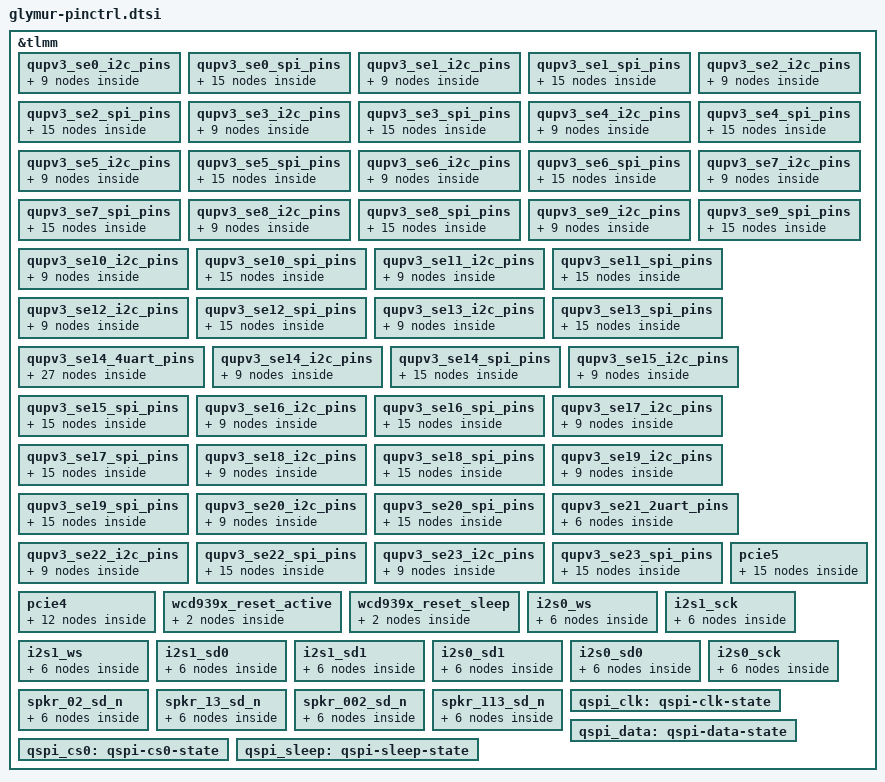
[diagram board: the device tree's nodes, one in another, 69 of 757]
// SPDX-License-Identifier: BSD-3-Clause
/*
 * Copyright (c) Qualcomm Technologies, Inc. and/or its subsidiaries.
 */

&tlmm {
	qupv3_se0_i2c_pins: qupv3_se0_i2c_pins {
		qupv3_se0_i2c_sda_active: qupv3_se0_i2c_sda_active {
			mux {
				pins = "gpio0";
				function = "qup0_se0";
			};

			config {
				pins = "gpio0";
				drive-strength = <2>;
				bias-pull-up;
				qcom,i2c_pull;
			};
		};

		qupv3_se0_i2c_scl_active: qupv3_se0_i2c_scl_active {
			mux {
				pins = "gpio1";
				function = "qup0_se0";
			};

			config {
				pins = "gpio1";
				drive-strength = <2>;
				bias-pull-up;
				qcom,i2c_pull;
			};
		};

		qupv3_se0_i2c_sleep: qupv3_se0_i2c_sleep {
			mux {
				pins = "gpio0", "gpio1";
				function = "gpio";
			};

			config {
				pins = "gpio0", "gpio1";
				drive-strength = <2>;
			};
		};
	};

	qupv3_se0_spi_pins: qupv3_se0_spi_pins {
		qupv3_se0_spi_miso_active: qupv3_se0_spi_miso_active {
			mux {
				pins = "gpio0";
				function = "qup0_se0";
			};

			config {
				pins = "gpio0";
				drive-strength = <6>;
				bias-disable;
			};
		};

		qupv3_se0_spi_mosi_active: qupv3_se0_spi_mosi_active {
			mux {
				pins = "gpio1";
				function = "qup0_se0";
			};

			config {
				pins = "gpio1";
				drive-strength = <6>;
				bias-disable;
			};
		};

		qupv3_se0_spi_clk_active: qupv3_se0_spi_clk_active {
			mux {
				pins = "gpio2";
				function = "qup0_se0";
			};

			config {
				pins = "gpio2";
				drive-strength = <6>;
				bias-disable;
			};
		};

		qupv3_se0_spi_cs_active: qupv3_se0_spi_cs_active {
			mux {
				pins = "gpio3";
				function = "qup0_se0";
			};

			config {
				pins = "gpio3";
				drive-strength = <6>;
				bias-disable;
			};
		};

		qupv3_se0_spi_sleep: qupv3_se0_spi_sleep {
			mux {
				pins = "gpio0", "gpio1",
				       "gpio2", "gpio3";
				function = "gpio";
			};

			config {
				pins = "gpio0", "gpio1",
				       "gpio2", "gpio3";
				drive-strength = <2>;
				bias-disable;
			};
		};
	};

	qupv3_se1_i2c_pins: qupv3_se1_i2c_pins {
		qupv3_se1_i2c_sda_active: qupv3_se1_i2c_sda_active {
			mux {
				pins = "gpio4";
				function = "qup0_se1";
			};

			config {
				pins = "gpio4";
				drive-strength = <2>;
				bias-pull-up;
				qcom,i2c_pull;
			};
		};

		qupv3_se1_i2c_scl_active: qupv3_se1_i2c_scl_active {
			mux {
				pins = "gpio5";
				function = "qup0_se1";
			};

			config {
				pins = "gpio5";
				drive-strength = <2>;
				bias-pull-up;
				qcom,i2c_pull;
			};
		};

		qupv3_se1_i2c_sleep: qupv3_se1_i2c_sleep {
			mux {
				pins = "gpio4", "gpio5";
				function = "gpio";
			};

			config {
				pins = "gpio4", "gpio5";
				drive-strength = <2>;
			};
		};
	};

	qupv3_se1_spi_pins: qupv3_se1_spi_pins {
		qupv3_se1_spi_miso_active: qupv3_se1_spi_miso_active {
			mux {
				pins = "gpio4";
				function = "qup0_se1";
			};

			config {
				pins = "gpio4";
				drive-strength = <6>;
				bias-disable;
			};
		};

		qupv3_se1_spi_mosi_active: qupv3_se1_spi_mosi_active {
			mux {
				pins = "gpio5";
				function = "qup0_se1";
			};

			config {
				pins = "gpio5";
				drive-strength = <6>;
				bias-disable;
			};
		};

		qupv3_se1_spi_clk_active: qupv3_se1_spi_clk_active {
			mux {
				pins = "gpio6";
				function = "qup0_se1";
			};

			config {
				pins = "gpio6";
				drive-strength = <6>;
				bias-disable;
			};
		};

		qupv3_se1_spi_cs_active: qupv3_se1_spi_cs_active {
			mux {
				pins = "gpio7";
				function = "qup0_se1";
			};

			config {
				pins = "gpio7";
				drive-strength = <6>;
				bias-disable;
			};
		};

		qupv3_se1_spi_sleep: qupv3_se1_spi_sleep {
			mux {
				pins = "gpio4", "gpio5",
				       "gpio6", "gpio7";
				function = "gpio";
			};

			config {
				pins = "gpio4", "gpio5",
				       "gpio6", "gpio7";
				drive-strength = <2>;
				bias-disable;
			};
		};
	};

	qupv3_se2_i2c_pins: qupv3_se2_i2c_pins {
		qupv3_se2_i2c_sda_active: qupv3_se2_i2c_sda_active {
			mux {
				pins = "gpio8";
				function = "qup0_se2";
			};

			config {
				pins = "gpio8";
				drive-strength = <2>;
				bias-pull-up;
				qcom,i2c_pull;
			};
		};

		qupv3_se2_i2c_scl_active: qupv3_se2_i2c_scl_active {
			mux {
				pins = "gpio9";
				function = "qup0_se2";
			};

			config {
				pins = "gpio9";
				drive-strength = <2>;
				bias-pull-up;
				qcom,i2c_pull;
			};
		};

		qupv3_se2_i2c_sleep: qupv3_se2_i2c_sleep {
			mux {
				pins = "gpio8", "gpio9";
				function = "gpio";
			};

			config {
				pins = "gpio8", "gpio9";
				drive-strength = <2>;
			};
		};
	};

	qupv3_se2_spi_pins: qupv3_se2_spi_pins {
		qupv3_se2_spi_miso_active: qupv3_se2_spi_miso_active {
			mux {
				pins = "gpio8";
				function = "qup0_se2";
			};

			config {
				pins = "gpio8";
				drive-strength = <6>;
				bias-disable;
			};
		};

		qupv3_se2_spi_mosi_active: qupv3_se2_spi_mosi_active {
			mux {
				pins = "gpio9";
				function = "qup0_se2";
			};

			config {
				pins = "gpio9";
				drive-strength = <6>;
				bias-disable;
			};
		};

		qupv3_se2_spi_clk_active: qupv3_se2_spi_clk_active {
			mux {
				pins = "gpio10";
				function = "qup0_se2";
			};

			config {
				pins = "gpio10";
				drive-strength = <6>;
				bias-disable;
			};
		};

		qupv3_se2_spi_cs_active: qupv3_se2_spi_cs_active {
			mux {
				pins = "gpio11";
				function = "qup0_se2";
			};

			config {
				pins = "gpio11";
				drive-strength = <6>;
				bias-disable;
			};
		};

		qupv3_se2_spi_sleep: qupv3_se2_spi_sleep {
			mux {
				pins = "gpio8", "gpio9",
				       "gpio10", "gpio11";
				function = "gpio";
			};

			config {
				pins = "gpio8", "gpio9",
				       "gpio10", "gpio11";
				drive-strength = <2>;
				bias-disable;
			};
		};
	};

	qupv3_se3_i2c_pins: qupv3_se3_i2c_pins {
		qupv3_se3_i2c_sda_active: qupv3_se3_i2c_sda_active {
			mux {
				pins = "gpio12";
				function = "qup0_se3";
			};

			config {
				pins = "gpio12";
				drive-strength = <2>;
				bias-pull-up;
				qcom,i2c_pull;
			};
		};

		qupv3_se3_i2c_scl_active: qupv3_se3_i2c_scl_active {
			mux {
				pins = "gpio13";
				function = "qup0_se3";
			};

			config {
				pins = "gpio13";
				drive-strength = <2>;
				bias-pull-up;
				qcom,i2c_pull;
			};
		};

		qupv3_se3_i2c_sleep: qupv3_se3_i2c_sleep {
			mux {
				pins = "gpio12", "gpio13";
				function = "gpio";
			};

			config {
				pins = "gpio12", "gpio13";
				drive-strength = <2>;
			};
		};
	};

	qupv3_se3_spi_pins: qupv3_se3_spi_pins {
		qupv3_se3_spi_miso_active: qupv3_se3_spi_miso_active {
			mux {
				pins = "gpio12";
				function = "qup0_se3";
			};

			config {
				pins = "gpio12";
				drive-strength = <6>;
				bias-disable;
			};
		};

		qupv3_se3_spi_mosi_active: qupv3_se3_spi_mosi_active {
			mux {
				pins = "gpio13";
				function = "qup0_se3";
			};

			config {
				pins = "gpio13";
				drive-strength = <6>;
				bias-disable;
			};
		};

		qupv3_se3_spi_clk_active: qupv3_se3_spi_clk_active {
			mux {
				pins = "gpio14";
				function = "qup0_se3";
			};

			config {
				pins = "gpio14";
				drive-strength = <6>;
				bias-disable;
			};
		};

		qupv3_se3_spi_cs_active: qupv3_se3_spi_cs_active {
			mux {
				pins = "gpio15";
				function = "qup0_se3";
			};

			config {
				pins = "gpio15";
				drive-strength = <6>;
				bias-disable;
			};
		};

		qupv3_se3_spi_sleep: qupv3_se3_spi_sleep {
			mux {
				pins = "gpio12", "gpio13",
				       "gpio14", "gpio15";
				function = "gpio";
			};

			config {
				pins = "gpio12", "gpio13",
				       "gpio14", "gpio15";
				drive-strength = <2>;
				bias-disable;
			};
		};
	};

	qupv3_se4_i2c_pins: qupv3_se4_i2c_pins {
		qupv3_se4_i2c_sda_active: qupv3_se4_i2c_sda_active {
			mux {
				pins = "gpio16";
				function = "qup0_se4";
			};

			config {
				pins = "gpio16";
				drive-strength = <2>;
				bias-pull-up;
				qcom,i2c_pull;
			};
		};

		qupv3_se4_i2c_scl_active: qupv3_se4_i2c_scl_active {
			mux {
				pins = "gpio17";
				function = "qup0_se4";
			};

			config {
				pins = "gpio17";
				drive-strength = <2>;
				bias-pull-up;
				qcom,i2c_pull;
			};
		};

		qupv3_se4_i2c_sleep: qupv3_se4_i2c_sleep {
			mux {
				pins = "gpio16", "gpio17";
				function = "gpio";
			};

			config {
				pins = "gpio16", "gpio17";
				drive-strength = <2>;
			};
		};
	};

	qupv3_se4_spi_pins: qupv3_se4_spi_pins {
		qupv3_se4_spi_miso_active: qupv3_se4_spi_miso_active {
			mux {
				pins = "gpio16";
				function = "qup0_se4";
			};

			config {
				pins = "gpio16";
				drive-strength = <6>;
				bias-disable;
			};
		};

		qupv3_se4_spi_mosi_active: qupv3_se4_spi_mosi_active {
			mux {
				pins = "gpio17";
				function = "qup0_se4";
			};

			config {
				pins = "gpio17";
				drive-strength = <6>;
				bias-disable;
			};
		};

		qupv3_se4_spi_clk_active: qupv3_se4_spi_clk_active {
			mux {
				pins = "gpio18";
				function = "qup0_se4";
			};

			config {
				pins = "gpio18";
				drive-strength = <6>;
				bias-disable;
			};
		};

		qupv3_se4_spi_cs_active: qupv3_se4_spi_cs_active {
			mux {
				pins = "gpio19";
				function = "qup0_se4";
			};

			config {
				pins = "gpio19";
				drive-strength = <6>;
				bias-disable;
			};
		};

		qupv3_se4_spi_sleep: qupv3_se4_spi_sleep {
			mux {
				pins = "gpio16", "gpio17",
				       "gpio18", "gpio19";
				function = "gpio";
			};

			config {
				pins = "gpio16", "gpio17",
				       "gpio18", "gpio19";
				drive-strength = <2>;
				bias-disable;
			};
		};
	};

	qupv3_se5_i2c_pins: qupv3_se5_i2c_pins {
		qupv3_se5_i2c_sda_active: qupv3_se5_i2c_sda_active {
			mux {
				pins = "gpio20";
				function = "qup0_se5";
			};

			config {
				pins = "gpio20";
				drive-strength = <2>;
				bias-pull-up;
				qcom,i2c_pull;
			};
		};

		qupv3_se5_i2c_scl_active: qupv3_se5_i2c_scl_active {
			mux {
				pins = "gpio21";
				function = "qup0_se5";
			};

			config {
				pins = "gpio21";
				drive-strength = <2>;
				bias-pull-up;
				qcom,i2c_pull;
			};
		};

		qupv3_se5_i2c_sleep: qupv3_se5_i2c_sleep {
			mux {
				pins = "gpio20", "gpio21";
				function = "gpio";
			};

			config {
				pins = "gpio20", "gpio21";
				drive-strength = <2>;
			};
		};
	};

	qupv3_se5_spi_pins: qupv3_se5_spi_pins {
		qupv3_se5_spi_miso_active: qupv3_se5_spi_miso_active {
			mux {
				pins = "gpio20";
				function = "qup0_se5";
			};

			config {
				pins = "gpio20";
				drive-strength = <6>;
				bias-disable;
			};
		};

		qupv3_se5_spi_mosi_active: qupv3_se5_spi_mosi_active {
			mux {
				pins = "gpio21";
				function = "qup0_se5";
			};

			config {
				pins = "gpio21";
				drive-strength = <6>;
				bias-disable;
			};
		};

		qupv3_se5_spi_clk_active: qupv3_se5_spi_clk_active {
			mux {
				pins = "gpio22";
				function = "qup0_se5";
			};

			config {
				pins = "gpio22";
				drive-strength = <6>;
				bias-disable;
			};
		};

		qupv3_se5_spi_cs_active: qupv3_se5_spi_cs_active {
			mux {
				pins = "gpio23";
				function = "qup0_se5";
			};

			config {
				pins = "gpio23";
				drive-strength = <6>;
				bias-disable;
			};
		};

		qupv3_se5_spi_sleep: qupv3_se5_spi_sleep {
			mux {
				pins = "gpio20", "gpio21",
				       "gpio22", "gpio23";
				function = "gpio";
			};

			config {
				pins = "gpio20", "gpio21",
				       "gpio22", "gpio23";
				drive-strength = <2>;
				bias-disable;
			};
		};
	};

	qupv3_se6_i2c_pins: qupv3_se6_i2c_pins {
		qupv3_se6_i2c_sda_active: qupv3_se6_i2c_sda_active {
			mux {
				pins = "gpio6";
				function = "qup0_se6";
			};

			config {
				pins = "gpio6";
				drive-strength = <2>;
				bias-pull-up;
				qcom,i2c_pull;
			};
		};

		qupv3_se6_i2c_scl_active: qupv3_se6_i2c_scl_active {
			mux {
				pins = "gpio7";
				function = "qup0_se6";
			};

			config {
				pins = "gpio7";
				drive-strength = <2>;
				bias-pull-up;
				qcom,i2c_pull;
			};
		};

		qupv3_se6_i2c_sleep: qupv3_se6_i2c_sleep {
			mux {
				pins = "gpio6", "gpio7";
				function = "gpio";
			};

			config {
				pins = "gpio6", "gpio7";
				drive-strength = <2>;
			};
		};
	};

	qupv3_se6_spi_pins: qupv3_se6_spi_pins {
		qupv3_se6_spi_miso_active: qupv3_se6_spi_miso_active {
			mux {
				pins = "gpio6";
				function = "qup0_se6";
			};

			config {
				pins = "gpio6";
				drive-strength = <6>;
				bias-disable;
			};
		};

		qupv3_se6_spi_mosi_active: qupv3_se6_spi_mosi_active {
			mux {
				pins = "gpio7";
				function = "qup0_se6";
			};

			config {
				pins = "gpio7";
				drive-strength = <6>;
				bias-disable;
			};
		};

		qupv3_se6_spi_clk_active: qupv3_se6_spi_clk_active {
			mux {
				pins = "gpio4";
				function = "qup0_se6";
			};

			config {
				pins = "gpio4";
				drive-strength = <6>;
				bias-disable;
			};
		};

		qupv3_se6_spi_cs_active: qupv3_se6_spi_cs_active {
			mux {
				pins = "gpio5";
				function = "qup0_se6";
			};

			config {
				pins = "gpio5";
				drive-strength = <6>;
				bias-disable;
			};
		};

		qupv3_se6_spi_sleep: qupv3_se6_spi_sleep {
			mux {
				pins = "gpio4", "gpio5",
				       "gpio6", "gpio7";
				function = "gpio";
			};

			config {
				pins = "gpio6", "gpio7",
					"gpio4", "gpio5";
				drive-strength = <2>;
				bias-disable;
			};
		};
	};

	qupv3_se7_i2c_pins: qupv3_se7_i2c_pins {
		qupv3_se7_i2c_sda_active: qupv3_se7_i2c_sda_active {
			mux {
				pins = "gpio14";
				function = "qup0_se7";
			};

			config {
				pins = "gpio14";
				drive-strength = <2>;
				bias-pull-up;
				qcom,i2c_pull;
			};
		};

		qupv3_se7_i2c_scl_active: qupv3_se7_i2c_scl_active {
			mux {
				pins = "gpio15";
				function = "qup0_se7";
			};

			config {
				pins = "gpio15";
				drive-strength = <2>;
				bias-pull-up;
				qcom,i2c_pull;
			};
		};

		qupv3_se7_i2c_sleep: qupv3_se7_i2c_sleep {
			mux {
				pins = "gpio14", "gpio15";
				function = "gpio";
			};

			config {
				pins = "gpio14", "gpio15";
				drive-strength = <2>;
			};
		};
	};

	qupv3_se7_spi_pins: qupv3_se7_spi_pins {
		qupv3_se7_spi_miso_active: qupv3_se7_spi_miso_active {
			mux {
				pins = "gpio14";
				function = "qup0_se7";
			};

			config {
				pins = "gpio14";
				drive-strength = <6>;
				bias-disable;
			};
		};

		qupv3_se7_spi_mosi_active: qupv3_se7_spi_mosi_active {
			mux {
				pins = "gpio15";
				function = "qup0_se7";
			};

			config {
				pins = "gpio15";
				drive-strength = <6>;
				bias-disable;
			};
		};

		qupv3_se7_spi_clk_active: qupv3_se7_spi_clk_active {
			mux {
				pins = "gpio12";
				function = "qup0_se7";
			};

			config {
				pins = "gpio12";
				drive-strength = <6>;
				bias-disable;
			};
		};

		qupv3_se7_spi_cs_active: qupv3_se7_spi_cs_active {
			mux {
				pins = "gpio13";
				function = "qup0_se7";
			};

			config {
				pins = "gpio13";
				drive-strength = <6>;
				bias-disable;
			};
		};

		qupv3_se7_spi_sleep: qupv3_se7_spi_sleep {
			mux {
				pins = "gpio14", "gpio15",
				       "gpio12", "gpio13";
				function = "gpio";
			};

			config {
				pins = "gpio14", "gpio15",
				       "gpio12", "gpio13";
				drive-strength = <2>;
				bias-disable;
			};
		};
	};

	qupv3_se8_i2c_pins: qupv3_se8_i2c_pins {
		qupv3_se8_i2c_sda_active: qupv3_se8_i2c_sda_active {
			mux {
				pins = "gpio32";
				function = "qup1_se0";
			};

			config {
				pins = "gpio32";
				drive-strength = <2>;
				bias-pull-up;
				qcom,i2c_pull;
			};
		};

		qupv3_se8_i2c_scl_active: qupv3_se8_i2c_scl_active {
			mux {
				pins = "gpio33";
				function = "qup1_se0";
			};

			config {
				pins = "gpio33";
				drive-strength = <2>;
				bias-pull-up;
				qcom,i2c_pull;
			};
		};

		qupv3_se8_i2c_sleep: qupv3_se8_i2c_sleep {
			mux {
				pins = "gpio32", "gpio33";
				function = "gpio";
			};

			config {
				pins = "gpio32", "gpio33";
				drive-strength = <2>;
			};
		};
	};

	qupv3_se8_spi_pins: qupv3_se8_spi_pins {
		qupv3_se8_spi_miso_active: qupv3_se8_spi_miso_active {
			mux {
				pins = "gpio32";
				function = "qup1_se0";
			};

			config {
				pins = "gpio32";
				drive-strength = <6>;
				bias-disable;
			};
		};

		qupv3_se8_spi_mosi_active: qupv3_se8_spi_mosi_active {
			mux {
				pins = "gpio33";
				function = "qup1_se0";
			};

			config {
				pins = "gpio33";
				drive-strength = <6>;
				bias-disable;
			};
		};

		qupv3_se8_spi_clk_active: qupv3_se8_spi_clk_active {
			mux {
				pins = "gpio34";
				function = "qup1_se0";
			};

			config {
				pins = "gpio34";
				drive-strength = <6>;
				bias-disable;
			};
		};

		qupv3_se8_spi_cs_active: qupv3_se8_spi_cs_active {
			mux {
				pins = "gpio35";
				function = "qup1_se0";
			};

			config {
				pins = "gpio35";
				drive-strength = <6>;
				bias-disable;
			};
		};

		qupv3_se8_spi_sleep: qupv3_se8_spi_sleep {
			mux {
				pins = "gpio32", "gpio33",
				       "gpio34", "gpio35";
				function = "gpio";
			};

			config {
				pins = "gpio32", "gpio33",
				       "gpio34", "gpio35";
				drive-strength = <2>;
				bias-disable;
			};
		};
	};

	qupv3_se9_i2c_pins: qupv3_se9_i2c_pins {
		qupv3_se9_i2c_sda_active: qupv3_se9_i2c_sda_active {
			mux {
				pins = "gpio36";
				function = "qup1_se1";
			};

			config {
				pins = "gpio36";
				drive-strength = <2>;
				bias-pull-up;
				qcom,i2c_pull;
			};
		};

		qupv3_se9_i2c_scl_active: qupv3_se9_i2c_scl_active {
			mux {
				pins = "gpio37";
				function = "qup1_se1";
			};

			config {
				pins = "gpio37";
				drive-strength = <2>;
				bias-pull-up;
				qcom,i2c_pull;
			};
		};

		qupv3_se9_i2c_sleep: qupv3_se9_i2c_sleep {
			mux {
				pins = "gpio36", "gpio37";
				function = "gpio";
			};

			config {
				pins = "gpio36", "gpio37";
				drive-strength = <2>;
			};
		};
	};

	qupv3_se9_spi_pins: qupv3_se9_spi_pins {
		qupv3_se9_spi_miso_active: qupv3_se9_spi_miso_active {
			mux {
				pins = "gpio36";
				function = "qup1_se1";
			};

			config {
				pins = "gpio36";
				drive-strength = <6>;
				bias-disable;
			};
		};

		qupv3_se9_spi_mosi_active: qupv3_se9_spi_mosi_active {
			mux {
				pins = "gpio37";
				function = "qup1_se1";
			};

			config {
				pins = "gpio37";
				drive-strength = <6>;
				bias-disable;
			};
		};

		qupv3_se9_spi_clk_active: qupv3_se9_spi_clk_active {
			mux {
				pins = "gpio38";
				function = "qup1_se1";
			};

			config {
				pins = "gpio38";
				drive-strength = <6>;
				bias-disable;
			};
		};

		qupv3_se9_spi_cs_active: qupv3_se9_spi_cs_active {
			mux {
				pins = "gpio39";
				function = "qup1_se1";
			};

			config {
				pins = "gpio39";
				drive-strength = <6>;
				bias-disable;
			};
		};

		qupv3_se9_spi_sleep: qupv3_se9_spi_sleep {
			mux {
				pins = "gpio36", "gpio37",
				       "gpio38", "gpio39";
				function = "gpio";
			};

			config {
				pins = "gpio36", "gpio37",
				       "gpio38", "gpio39";
				drive-strength = <2>;
				bias-disable;
			};
		};
	};

	qupv3_se10_i2c_pins: qupv3_se10_i2c_pins {
		qupv3_se10_i2c_sda_active: qupv3_se10_i2c_sda_active {
			mux {
				pins = "gpio40";
				function = "qup1_se2";
			};

			config {
				pins = "gpio40";
				drive-strength = <2>;
				bias-pull-up;
				qcom,i2c_pull;
			};
		};

		qupv3_se10_i2c_scl_active: qupv3_se10_i2c_scl_active {
			mux {
				pins = "gpio41";
				function = "qup1_se2";
			};

			config {
				pins = "gpio41";
				drive-strength = <2>;
				bias-pull-up;
				qcom,i2c_pull;
			};
		};

		qupv3_se10_i2c_sleep: qupv3_se10_i2c_sleep {
			mux {
				pins = "gpio40", "gpio41";
				function = "gpio";
			};

			config {
				pins = "gpio40", "gpio41";
				drive-strength = <2>;
			};
		};
	};

	qupv3_se10_spi_pins: qupv3_se10_spi_pins {
		qupv3_se10_spi_miso_active: qupv3_se10_spi_miso_active {
			mux {
				pins = "gpio40";
				function = "qup1_se2";
			};

			config {
				pins = "gpio40";
				drive-strength = <6>;
				bias-disable;
			};
		};

		qupv3_se10_spi_mosi_active: qupv3_se10_spi_mosi_active {
			mux {
				pins = "gpio41";
				function = "qup1_se2";
			};

			config {
				pins = "gpio41";
				drive-strength = <6>;
				bias-disable;
			};
		};

		qupv3_se10_spi_clk_active: qupv3_se10_spi_clk_active {
			mux {
				pins = "gpio42";
				function = "qup1_se2";
			};

			config {
				pins = "gpio42";
				drive-strength = <6>;
				bias-disable;
			};
		};

		qupv3_se10_spi_cs_active: qupv3_se10_spi_cs_active {
			mux {
				pins = "gpio43";
				function = "qup1_se2";
			};

			config {
				pins = "gpio43";
				drive-strength = <6>;
				bias-disable;
			};
		};

		qupv3_se10_spi_sleep: qupv3_se10_spi_sleep {
			mux {
				pins = "gpio40", "gpio41",
				       "gpio42", "gpio43";
				function = "gpio";
			};

			config {
				pins = "gpio40", "gpio41",
				       "gpio42", "gpio43";
				drive-strength = <2>;
				bias-disable;
			};
		};
	};

	qupv3_se11_i2c_pins: qupv3_se11_i2c_pins {
		qupv3_se11_i2c_sda_active: qupv3_se11_i2c_sda_active {
			mux {
				pins = "gpio44";
				function = "qup1_se3";
			};

			config {
				pins = "gpio44";
				drive-strength = <2>;
				bias-pull-up;
				qcom,i2c_pull;
			};
		};

		qupv3_se11_i2c_scl_active: qupv3_se11_i2c_scl_active {
			mux {
				pins = "gpio45";
				function = "qup1_se3";
			};

			config {
				pins = "gpio45";
				drive-strength = <2>;
				bias-pull-up;
				qcom,i2c_pull;
			};
		};

		qupv3_se11_i2c_sleep: qupv3_se11_i2c_sleep {
			mux {
				pins = "gpio44", "gpio45";
				function = "gpio";
			};

			config {
				pins = "gpio44", "gpio45";
				drive-strength = <2>;
			};
		};
	};

	qupv3_se11_spi_pins: qupv3_se11_spi_pins {
		qupv3_se11_spi_miso_active: qupv3_se11_spi_miso_active {
			mux {
				pins = "gpio44";
				function = "qup1_se3";
			};

			config {
				pins = "gpio44";
				drive-strength = <6>;
				bias-disable;
			};
		};

		qupv3_se11_spi_mosi_active: qupv3_se11_spi_mosi_active {
			mux {
				pins = "gpio45";
				function = "qup1_se3";
			};

			config {
				pins = "gpio45";
				drive-strength = <6>;
				bias-disable;
			};
		};

		qupv3_se11_spi_clk_active: qupv3_se11_spi_clk_active {
			mux {
				pins = "gpio46";
				function = "qup1_se3";
			};

			config {
				pins = "gpio46";
				drive-strength = <6>;
				bias-disable;
			};
		};

		qupv3_se11_spi_cs_active: qupv3_se11_spi_cs_active {
			mux {
				pins = "gpio47";
				function = "qup1_se3";
			};

			config {
				pins = "gpio47";
				drive-strength = <6>;
				bias-disable;
			};
		};

		qupv3_se11_spi_sleep: qupv3_se11_spi_sleep {
			mux {
				pins = "gpio44", "gpio45",
				       "gpio46", "gpio47";
				function = "gpio";
			};

			config {
				pins = "gpio44", "gpio45",
				       "gpio46", "gpio47";
				drive-strength = <2>;
				bias-disable;
			};
		};
	};

	qupv3_se12_i2c_pins: qupv3_se12_i2c_pins {
		qupv3_se12_i2c_sda_active: qupv3_se12_i2c_sda_active {
			mux {
				pins = "gpio48";
				function = "qup1_se4";
			};

			config {
				pins = "gpio48";
				drive-strength = <2>;
				bias-pull-up;
				qcom,i2c_pull;
			};
		};

		qupv3_se12_i2c_scl_active: qupv3_se12_i2c_scl_active {
			mux {
				pins = "gpio49";
				function = "qup1_se4";
			};

			config {
				pins = "gpio49";
				drive-strength = <2>;
				bias-pull-up;
				qcom,i2c_pull;
			};
		};

		qupv3_se12_i2c_sleep: qupv3_se12_i2c_sleep {
			mux {
				pins = "gpio48", "gpio49";
				function = "gpio";
			};

			config {
				pins = "gpio48", "gpio49";
				drive-strength = <2>;
			};
		};
	};

	qupv3_se12_spi_pins: qupv3_se12_spi_pins {
		qupv3_se12_spi_miso_active: qupv3_se12_spi_miso_active {
			mux {
				pins = "gpio48";
				function = "qup1_se4";
			};

			config {
				pins = "gpio48";
				drive-strength = <6>;
				bias-disable;
			};
		};

		qupv3_se12_spi_mosi_active: qupv3_se12_spi_mosi_active {
			mux {
				pins = "gpio49";
				function = "qup1_se4";
			};

			config {
				pins = "gpio49";
				drive-strength = <6>;
				bias-disable;
			};
		};

		qupv3_se12_spi_clk_active: qupv3_se12_spi_clk_active {
			mux {
				pins = "gpio50";
				function = "qup1_se4";
			};

			config {
				pins = "gpio50";
				drive-strength = <6>;
				bias-disable;
			};
		};

		qupv3_se12_spi_cs_active: qupv3_se12_spi_cs_active {
			mux {
				pins = "gpio51";
				function = "qup1_se4";
			};

			config {
				pins = "gpio51";
				drive-strength = <6>;
				bias-disable;
			};
		};

		qupv3_se12_spi_sleep: qupv3_se12_spi_sleep {
			mux {
				pins = "gpio48", "gpio49",
				       "gpio50", "gpio51";
				function = "gpio";
			};

			config {
				pins = "gpio48", "gpio49",
				       "gpio50", "gpio51";
				drive-strength = <2>;
				bias-disable;
			};
		};
	};

	qupv3_se13_i2c_pins: qupv3_se13_i2c_pins {
		qupv3_se13_i2c_sda_active: qupv3_se13_i2c_sda_active {
			mux {
				pins = "gpio52";
				function = "qup1_se5";
			};

			config {
				pins = "gpio52";
				drive-strength = <2>;
				bias-pull-up;
				qcom,i2c_pull;
			};
		};

		qupv3_se13_i2c_scl_active: qupv3_se13_i2c_scl_active {
			mux {
				pins = "gpio53";
				function = "qup1_se5";
			};

			config {
				pins = "gpio53";
				drive-strength = <2>;
				bias-pull-up;
				qcom,i2c_pull;
			};
		};

		qupv3_se13_i2c_sleep: qupv3_se13_i2c_sleep {
			mux {
				pins = "gpio52", "gpio53";
				function = "gpio";
			};

			config {
				pins = "gpio52", "gpio53";
				drive-strength = <2>;
			};
		};
	};

	qupv3_se13_spi_pins: qupv3_se13_spi_pins {
		qupv3_se13_spi_miso_active: qupv3_se13_spi_miso_active {
			mux {
				pins = "gpio52";
				function = "qup1_se5";
			};

			config {
				pins = "gpio52";
				drive-strength = <6>;
				bias-disable;
			};
		};

		qupv3_se13_spi_mosi_active: qupv3_se13_spi_mosi_active {
			mux {
				pins = "gpio53";
				function = "qup1_se5";
			};

			config {
				pins = "gpio53";
				drive-strength = <6>;
				bias-disable;
			};
		};

		qupv3_se13_spi_clk_active: qupv3_se13_spi_clk_active {
			mux {
				pins = "gpio54";
				function = "qup1_se5";
			};

			config {
				pins = "gpio54";
				drive-strength = <6>;
				bias-disable;
			};
		};

		qupv3_se13_spi_cs_active: qupv3_se13_spi_cs_active {
			mux {
				pins = "gpio55";
				function = "qup1_se5";
			};

			config {
				pins = "gpio55";
				drive-strength = <6>;
				bias-disable;
			};
		};

		qupv3_se13_spi_sleep: qupv3_se13_spi_sleep {
			mux {
				pins = "gpio52", "gpio53",
				       "gpio54", "gpio55";
				function = "gpio";
			};

			config {
				pins = "gpio52", "gpio53",
				       "gpio54", "gpio55";
				drive-strength = <2>;
				bias-disable;
			};
		};
	};

	qupv3_se14_4uart_pins: qupv3_se14_4uart_pins {
		qupv3_se14_default_cts: qupv3_se14_default_cts {
			mux {
				pins = "gpio56";
				function = "gpio";
			};

			config {
				pins = "gpio56";
				drive-strength = <2>;
				bias-disable;
			};
		};

		qupv3_se14_default_rts: qupv3_se14_default_rts {
			mux {
				pins = "gpio57";
				function = "gpio";
			};

			config {
				pins = "gpio57";
				drive-strength = <2>;
				bias-pull-down;
			};
		};

		qupv3_se14_default_tx: qupv3_se14_default_tx {
			mux {
				pins = "gpio58";
				function = "gpio";
			};

			config {
				pins = "gpio58";
				drive-strength = <2>;
				bias-pull-up;
			};
		};

		qupv3_se14_default_rx: qupv3_se14_default_rx {
			mux {
				pins = "gpio59";
				function = "gpio";
			};

			config {
				pins = "gpio59";
				drive-strength = <2>;
				bias-pull-down;
			};
		};

		qupv3_se14_cts: qupv3_se14_cts {
			mux {
				pins = "gpio56";
				function = "qup1_se6";
			};

			config {
				pins = "gpio56";
				drive-strength = <2>;
				bias-disable;
			};
	       };

		qupv3_se14_rts: qupv3_se14_rts {
			mux {
				pins = "gpio57";
				function = "qup1_se6";
			};

			config {
				pins = "gpio57";
				drive-strength = <2>;
				bias-pull-down;
			};
	       };

		qupv3_se14_tx: qupv3_se14_tx {
			mux {
				pins = "gpio58";
				function = "qup1_se6";
			};

			config {
				pins = "gpio58";
				drive-strength = <2>;
				bias-pull-up;
			};
		};

		qupv3_se14_rx_active: qupv3_se14_rx_active {
			mux {
				pins = "gpio59";
				function = "qup1_se6";
			};

			config {
				pins = "gpio59";
				drive-strength = <2>;
				bias-disable;
			};
		};

		/* RX to be in gpio mode for sleep config */
		qupv3_se14_rx_wake: qupv3_se14_rx_wake {
			mux {
				pins = "gpio59";
				function = "gpio";
			};

			config {
				pins = "gpio59";
				drive-strength = <2>;
				bias-disable;
			};
		};
	};

	qupv3_se14_i2c_pins: qupv3_se14_i2c_pins {
		qupv3_se14_i2c_sda_active: qupv3_se14_i2c_sda_active {
			mux {
				pins = "gpio56";
				function = "qup1_se6";
			};

			config {
				pins = "gpio56";
				drive-strength = <2>;
				bias-pull-up;
				qcom,i2c_pull;
			};
		};

		qupv3_se14_i2c_scl_active: qupv3_se14_i2c_scl_active {
			mux {
				pins = "gpio57";
				function = "qup1_se6";
			};

			config {
				pins = "gpio57";
				drive-strength = <2>;
				bias-pull-up;
				qcom,i2c_pull;
			};
		};

		qupv3_se14_i2c_sleep: qupv3_se14_i2c_sleep {
			mux {
				pins = "gpio56", "gpio57";
				function = "gpio";
			};

			config {
				pins = "gpio56", "gpio57";
				drive-strength = <2>;
			};
		};
	};

	qupv3_se14_spi_pins: qupv3_se14_spi_pins {
		qupv3_se14_spi_miso_active: qupv3_se14_spi_miso_active {
			mux {
				pins = "gpio56";
				function = "qup1_se6";
			};

			config {
				pins = "gpio56";
				drive-strength = <6>;
				bias-disable;
			};
		};

		qupv3_se14_spi_mosi_active: qupv3_se14_spi_mosi_active {
			mux {
				pins = "gpio57";
				function = "qup1_se6";
			};

			config {
				pins = "gpio57";
				drive-strength = <6>;
				bias-disable;
			};
		};

		qupv3_se14_spi_clk_active: qupv3_se14_spi_clk_active {
			mux {
				pins = "gpio58";
				function = "qup1_se6";
			};

			config {
				pins = "gpio58";
				drive-strength = <6>;
				bias-disable;
			};
		};

		qupv3_se14_spi_cs_active: qupv3_se14_spi_cs_active {
			mux {
				pins = "gpio59";
				function = "qup1_se6";
			};

			config {
				pins = "gpio59";
				drive-strength = <6>;
				bias-disable;
			};
		};

		qupv3_se14_spi_sleep: qupv3_se14_spi_sleep {
			mux {
				pins = "gpio56", "gpio57",
				       "gpio58", "gpio59";
				function = "gpio";
			};

			config {
				pins = "gpio56", "gpio57",
				       "gpio58", "gpio59";
				drive-strength = <2>;
				bias-disable;
			};
		};
	};

	qupv3_se15_i2c_pins: qupv3_se15_i2c_pins {
		qupv3_se15_i2c_sda_active: qupv3_se15_i2c_sda_active {
			mux {
				pins = "gpio54";
				function = "qup1_se7";
			};

			config {
				pins = "gpio54";
				drive-strength = <2>;
				bias-pull-up;
				qcom,i2c_pull;
			};
		};

		qupv3_se15_i2c_scl_active: qupv3_se15_i2c_scl_active {
			mux {
				pins = "gpio55";
				function = "qup1_se7";
			};

			config {
				pins = "gpio55";
				drive-strength = <2>;
				bias-pull-up;
				qcom,i2c_pull;
			};
		};

		qupv3_se15_i2c_sleep: qupv3_se15_i2c_sleep {
			mux {
				pins = "gpio54", "gpio55";
				function = "gpio";
			};

			config {
				pins = "gpio54", "gpio55";
				drive-strength = <2>;
			};
		};
	};

	qupv3_se15_spi_pins: qupv3_se15_spi_pins {
		qupv3_se15_spi_miso_active: qupv3_se15_spi_miso_active {
			mux {
				pins = "gpio54";
				function = "qup1_se7";
			};

			config {
				pins = "gpio54";
				drive-strength = <6>;
				bias-disable;
			};
		};

		qupv3_se15_spi_mosi_active: qupv3_se15_spi_mosi_active {
			mux {
				pins = "gpio55";
				function = "qup1_se7";
			};

			config {
				pins = "gpio55";
				drive-strength = <6>;
				bias-disable;
			};
		};

		qupv3_se15_spi_clk_active: qupv3_se15_spi_clk_active {
			mux {
				pins = "gpio52";
				function = "qup1_se7";
			};

			config {
				pins = "gpio52";
				drive-strength = <6>;
				bias-disable;
			};
		};

		qupv3_se15_spi_cs_active: qupv3_se15_spi_cs_active {
			mux {
				pins = "gpio53";
				function = "qup1_se7";
			};

			config {
				pins = "gpio53";
				drive-strength = <6>;
				bias-disable;
			};
		};

		qupv3_se15_spi_sleep: qupv3_se15_spi_sleep {
			mux {
				pins = "gpio54", "gpio55",
				       "gpio52", "gpio53";
				function = "gpio";
			};

			config {
				pins = "gpio54", "gpio55",
				       "gpio52", "gpio53";
				drive-strength = <2>;
				bias-disable;
			};
		};
	};

	qupv3_se16_i2c_pins: qupv3_se16_i2c_pins {
		qupv3_se16_i2c_sda_active: qupv3_se16_i2c_sda_active {
			mux {
				pins = "gpio64";
				function = "qup2_se0";
			};

			config {
				pins = "gpio64";
				drive-strength = <2>;
				bias-pull-up;
				qcom,i2c_pull;
			};
		};

		qupv3_se16_i2c_scl_active: qupv3_se16_i2c_scl_active {
			mux {
				pins = "gpio65";
				function = "qup2_se0";
			};

			config {
				pins = "gpio65";
				drive-strength = <2>;
				bias-pull-up;
				qcom,i2c_pull;
			};
		};

		qupv3_se16_i2c_sleep: qupv3_se16_i2c_sleep {
			mux {
				pins = "gpio64", "gpio65";
				function = "gpio";
			};

			config {
				pins = "gpio64", "gpio65";
				drive-strength = <2>;
			};
		};
	};

	qupv3_se16_spi_pins: qupv3_se16_spi_pins {
		qupv3_se16_spi_miso_active: qupv3_se16_spi_miso_active {
			mux {
				pins = "gpio64";
				function = "qup2_se0";
			};

			config {
				pins = "gpio64";
				drive-strength = <6>;
				bias-disable;
			};
		};

		qupv3_se16_spi_mosi_active: qupv3_se16_spi_mosi_active {
			mux {
				pins = "gpio65";
				function = "qup2_se0";
			};

			config {
				pins = "gpio65";
				drive-strength = <6>;
				bias-disable;
			};
		};

		qupv3_se16_spi_clk_active: qupv3_se16_spi_clk_active {
			mux {
				pins = "gpio66";
				function = "qup2_se0";
			};

			config {
				pins = "gpio66";
				drive-strength = <6>;
				bias-disable;
			};
		};

		qupv3_se16_spi_cs_active: qupv3_se16_spi_cs_active {
			mux {
				pins = "gpio67";
				function = "qup2_se0";
			};

			config {
				pins = "gpio67";
				drive-strength = <6>;
				bias-disable;
			};
		};

		qupv3_se16_spi_sleep: qupv3_se16_spi_sleep {
			mux {
				pins = "gpio64", "gpio65",
				       "gpio66", "gpio67";
				function = "gpio";
			};

			config {
				pins = "gpio64", "gpio65",
				       "gpio66", "gpio67";
				drive-strength = <2>;
				bias-disable;
			};
		};
	};

	qupv3_se17_i2c_pins: qupv3_se17_i2c_pins {
		qupv3_se17_i2c_sda_active: qupv3_se17_i2c_sda_active {
			mux {
				pins = "gpio68";
				function = "qup2_se1";
			};

			config {
				pins = "gpio68";
				drive-strength = <2>;
				bias-pull-up;
				qcom,i2c_pull;
			};
		};

		qupv3_se17_i2c_scl_active: qupv3_se17_i2c_scl_active {
			mux {
				pins = "gpio69";
				function = "qup2_se1";
			};

			config {
				pins = "gpio69";
				drive-strength = <2>;
				bias-pull-up;
				qcom,i2c_pull;
			};
		};

		qupv3_se17_i2c_sleep: qupv3_se17_i2c_sleep {
			mux {
				pins = "gpio68", "gpio69";
				function = "gpio";
			};

			config {
				pins = "gpio68", "gpio69";
				drive-strength = <2>;
			};
		};
	};

	qupv3_se17_spi_pins: qupv3_se17_spi_pins {
		qupv3_se17_spi_miso_active: qupv3_se17_spi_miso_active {
			mux {
				pins = "gpio68";
				function = "qup2_se1";
			};

			config {
				pins = "gpio68";
				drive-strength = <6>;
				bias-disable;
			};
		};

		qupv3_se17_spi_mosi_active: qupv3_se17_spi_mosi_active {
			mux {
				pins = "gpio69";
				function = "qup2_se1";
			};

			config {
				pins = "gpio69";
				drive-strength = <6>;
				bias-disable;
			};
		};

		qupv3_se17_spi_clk_active: qupv3_se17_spi_clk_active {
			mux {
				pins = "gpio70";
				function = "qup2_se1";
			};

			config {
				pins = "gpio70";
				drive-strength = <6>;
				bias-disable;
			};
		};

		qupv3_se17_spi_cs_active: qupv3_se17_spi_cs_active {
			mux {
				pins = "gpio71";
				function = "qup2_se1";
			};

			config {
				pins = "gpio71";
				drive-strength = <6>;
				bias-disable;
			};
		};

		qupv3_se17_spi_sleep: qupv3_se17_spi_sleep {
			mux {
				pins = "gpio68", "gpio69",
				       "gpio70", "gpio71";
				function = "gpio";
			};

			config {
				pins = "gpio68", "gpio69",
				       "gpio70", "gpio71";
				drive-strength = <2>;
				bias-disable;
			};
		};
	};

	qupv3_se18_i2c_pins: qupv3_se18_i2c_pins {
		qupv3_se18_i2c_sda_active: qupv3_se18_i2c_sda_active {
			mux {
				pins = "gpio72";
				function = "qup2_se2";
			};

			config {
				pins = "gpio72";
				drive-strength = <2>;
				bias-pull-up;
				qcom,i2c_pull;
			};
		};

		qupv3_se18_i2c_scl_active: qupv3_se18_i2c_scl_active {
			mux {
				pins = "gpio73";
				function = "qup2_se2";
			};

			config {
				pins = "gpio73";
				drive-strength = <2>;
				bias-pull-up;
				qcom,i2c_pull;
			};
		};

		qupv3_se18_i2c_sleep: qupv3_se18_i2c_sleep {
			mux {
				pins = "gpio72", "gpio73";
				function = "gpio";
			};

			config {
				pins = "gpio72", "gpio73";
				drive-strength = <2>;
			};
		};
	};

	qupv3_se18_spi_pins: qupv3_se18_spi_pins {
		qupv3_se18_spi_miso_active: qupv3_se18_spi_miso_active {
			mux {
				pins = "gpio72";
				function = "qup2_se2";
			};

			config {
				pins = "gpio72";
				drive-strength = <6>;
				bias-disable;
			};
		};

		qupv3_se18_spi_mosi_active: qupv3_se18_spi_mosi_active {
			mux {
				pins = "gpio73";
				function = "qup2_se2";
			};

			config {
				pins = "gpio73";
				drive-strength = <6>;
				bias-disable;
			};
		};

		qupv3_se18_spi_clk_active: qupv3_se18_spi_clk_active {
			mux {
				pins = "gpio74";
				function = "qup2_se2";
			};

			config {
				pins = "gpio74";
				drive-strength = <6>;
				bias-disable;
			};
		};

		qupv3_se18_spi_cs_active: qupv3_se18_spi_cs_active {
			mux {
				pins = "gpio75";
				function = "qup2_se2";
			};

			config {
				pins = "gpio75";
				drive-strength = <6>;
				bias-disable;
			};
		};

		qupv3_se18_spi_sleep: qupv3_se18_spi_sleep {
			mux {
				pins = "gpio72", "gpio73",
				       "gpio74", "gpio75";
				function = "gpio";
			};

			config {
				pins = "gpio72", "gpio73",
				       "gpio74", "gpio75";
				drive-strength = <2>;
				bias-disable;
			};
		};
	};

	qupv3_se19_i2c_pins: qupv3_se19_i2c_pins {
		qupv3_se19_i2c_sda_active: qupv3_se19_i2c_sda_active {
			mux {
				pins = "gpio76";
				function = "qup2_se3";
			};

			config {
				pins = "gpio76";
				drive-strength = <2>;
				bias-pull-up;
				qcom,i2c_pull;
			};
		};

		qupv3_se19_i2c_scl_active: qupv3_se19_i2c_scl_active {
			mux {
				pins = "gpio77";
				function = "qup2_se3";
			};

			config {
				pins = "gpio77";
				drive-strength = <2>;
				bias-pull-up;
				qcom,i2c_pull;
			};
		};

		qupv3_se19_i2c_sleep: qupv3_se19_i2c_sleep {
			mux {
				pins = "gpio76", "gpio77";
				function = "gpio";
			};

			config {
				pins = "gpio76", "gpio77";
				drive-strength = <2>;
			};
		};
	};

	qupv3_se19_spi_pins: qupv3_se19_spi_pins {
		qupv3_se19_spi_miso_active: qupv3_se19_spi_miso_active {
			mux {
				pins = "gpio76";
				function = "qup2_se3";
			};

			config {
				pins = "gpio76";
				drive-strength = <6>;
				bias-disable;
			};
		};

		qupv3_se19_spi_mosi_active: qupv3_se19_spi_mosi_active {
			mux {
				pins = "gpio77";
				function = "qup2_se3";
			};

			config {
				pins = "gpio77";
				drive-strength = <6>;
				bias-disable;
			};
		};

		qupv3_se19_spi_clk_active: qupv3_se19_spi_clk_active {
			mux {
				pins = "gpio78";
				function = "qup2_se3";
			};

			config {
				pins = "gpio78";
				drive-strength = <6>;
				bias-disable;
			};
		};

		qupv3_se19_spi_cs_active: qupv3_se19_spi_cs_active {
			mux {
				pins = "gpio79";
				function = "qup2_se3";
			};

			config {
				pins = "gpio79";
				drive-strength = <6>;
				bias-disable;
			};
		};

		qupv3_se19_spi_sleep: qupv3_se19_spi_sleep {
			mux {
				pins = "gpio76", "gpio77",
				       "gpio78", "gpio79";
				function = "gpio";
			};

			config {
				pins = "gpio76", "gpio77",
				       "gpio78", "gpio79";
				drive-strength = <2>;
				bias-disable;
			};
		};
	};

	qupv3_se20_i2c_pins: qupv3_se20_i2c_pins {
		qupv3_se20_i2c_sda_active: qupv3_se20_i2c_sda_active {
			mux {
				pins = "gpio80";
				function = "qup2_se4";
			};

			config {
				pins = "gpio80";
				drive-strength = <2>;
				bias-pull-up;
				qcom,i2c_pull;
			};
		};

		qupv3_se20_i2c_scl_active: qupv3_se20_i2c_scl_active {
			mux {
				pins = "gpio81";
				function = "qup2_se4";
			};

			config {
				pins = "gpio81";
				drive-strength = <2>;
				bias-pull-up;
				qcom,i2c_pull;
			};
		};

		qupv3_se20_i2c_sleep: qupv3_se20_i2c_sleep {
			mux {
				pins = "gpio80", "gpio81";
				function = "gpio";
			};

			config {
				pins = "gpio80", "gpio81";
				drive-strength = <2>;
			};
		};
	};

	qupv3_se20_spi_pins: qupv3_se20_spi_pins {
		qupv3_se20_spi_miso_active: qupv3_se20_spi_miso_active {
			mux {
				pins = "gpio80";
				function = "qup2_se4";
			};

			config {
				pins = "gpio80";
				drive-strength = <6>;
				bias-disable;
			};
		};

		qupv3_se20_spi_mosi_active: qupv3_se20_spi_mosi_active {
			mux {
				pins = "gpio81";
				function = "qup2_se4";
			};

			config {
				pins = "gpio81";
				drive-strength = <6>;
				bias-disable;
			};
		};

		qupv3_se20_spi_clk_active: qupv3_se20_spi_clk_active {
			mux {
				pins = "gpio82";
				function = "qup2_se4";
			};

			config {
				pins = "gpio82";
				drive-strength = <6>;
				bias-disable;
			};
		};

		qupv3_se20_spi_cs_active: qupv3_se20_spi_cs_active {
			mux {
				pins = "gpio83";
				function = "qup2_se4";
			};

			config {
				pins = "gpio83";
				drive-strength = <6>;
				bias-disable;
			};
		};

		qupv3_se20_spi_sleep: qupv3_se20_spi_sleep {
			mux {
				pins = "gpio80", "gpio81",
				       "gpio82", "gpio83";
				function = "gpio";
			};

			config {
				pins = "gpio80", "gpio81",
				       "gpio82", "gpio83";
				drive-strength = <2>;
				bias-disable;
			};
		};
	};

	qupv3_se21_2uart_pins: qupv3_se21_2uart_pins {
		qupv3_se21_2uart_active: qupv3_se21_2uart_active {
			mux {
				pins = "gpio86", "gpio87";
				function = "qup2_se5";
			};

			config {
				pins = "gpio86", "gpio87";
				drive-strength= <2>;
				bias-disable;
			};
		};

		qupv3_se21_2uart_sleep: qupv3_se21_2uart_sleep {
			mux {
				pins = "gpio86", "gpio87";
				function = "gpio";
			};

			config {
				pins = "gpio86", "gpio87";
				drive-strength = <2>;
				bias-pull-down;
			};
		};

	};

	qupv3_se22_i2c_pins: qupv3_se22_i2c_pins {
		qupv3_se22_i2c_sda_active: qupv3_se22_i2c_sda_active {
			mux {
				pins = "gpio88";
				function = "qup2_se6";
			};

			config {
				pins = "gpio88";
				drive-strength = <2>;
				bias-pull-up;
				qcom,i2c_pull;
			};
		};

		qupv3_se22_i2c_scl_active: qupv3_se22_i2c_scl_active {
			mux {
				pins = "gpio89";
				function = "qup2_se6";
			};

			config {
				pins = "gpio89";
				drive-strength = <2>;
				bias-pull-up;
				qcom,i2c_pull;
			};
		};

		qupv3_se22_i2c_sleep: qupv3_se22_i2c_sleep {
			mux {
				pins = "gpio88", "gpio89";
				function = "gpio";
			};

			config {
				pins = "gpio88", "gpio89";
				drive-strength = <2>;
			};
		};
	};

	qupv3_se22_spi_pins: qupv3_se22_spi_pins {
		qupv3_se22_spi_miso_active: qupv3_se22_spi_miso_active {
			mux {
				pins = "gpio88";
				function = "qup2_se6";
			};

			config {
				pins = "gpio88";
				drive-strength = <6>;
				bias-disable;
			};
		};

		qupv3_se22_spi_mosi_active: qupv3_se22_spi_mosi_active {
			mux {
				pins = "gpio89";
				function = "qup2_se6";
			};

			config {
				pins = "gpio89";
				drive-strength = <6>;
				bias-disable;
			};
		};

		qupv3_se22_spi_clk_active: qupv3_se22_spi_clk_active {
			mux {
				pins = "gpio90";
				function = "qup2_se6";
			};

			config {
				pins = "gpio90";
				drive-strength = <6>;
				bias-disable;
			};
		};

		qupv3_se22_spi_cs_active: qupv3_se22_spi_cs_active {
			mux {
				pins = "gpio91";
				function = "qup2_se6";
			};

			config {
				pins = "gpio91";
				drive-strength = <6>;
				bias-disable;
			};
		};

		qupv3_se22_spi_sleep: qupv3_se22_spi_sleep {
			mux {
				pins = "gpio88", "gpio89",
				       "gpio90", "gpio91";
				function = "gpio";
			};

			config {
				pins = "gpio88", "gpio89",
				       "gpio90", "gpio91";
				drive-strength = <2>;
				bias-disable;
			};
		};
	};

	qupv3_se23_i2c_pins: qupv3_se23_i2c_pins {
		qupv3_se23_i2c_sda_active: qupv3_se23_i2c_sda_active {
			mux {
				pins = "gpio80";
				function = "qup2_se7";
			};

			config {
				pins = "gpio80";
				drive-strength = <2>;
				bias-pull-up;
				qcom,i2c_pull;
			};
		};

		qupv3_se23_i2c_scl_active: qupv3_se23_i2c_scl_active {
			mux {
				pins = "gpio81";
				function = "qup2_se7";
			};

			config {
				pins = "gpio81";
				drive-strength = <2>;
				bias-pull-up;
				qcom,i2c_pull;
			};
		};

		qupv3_se23_i2c_sleep: qupv3_se23_i2c_sleep {
			mux {
				pins = "gpio80", "gpio81";
				function = "gpio";
			};

			config {
				pins = "gpio80", "gpio81";
				drive-strength = <2>;
			};
		};
	};

	qupv3_se23_spi_pins: qupv3_se23_spi_pins {
		qupv3_se23_spi_miso_active: qupv3_se23_spi_miso_active {
			mux {
				pins = "gpio80";
				function = "qup2_se7";
			};

			config {
				pins = "gpio80";
				drive-strength = <6>;
				bias-disable;
			};
		};

		qupv3_se23_spi_mosi_active: qupv3_se23_spi_mosi_active {
			mux {
				pins = "gpio81";
				function = "qup2_se7";
			};

			config {
				pins = "gpio81";
				drive-strength = <6>;
				bias-disable;
			};
		};

		qupv3_se23_spi_clk_active: qupv3_se23_spi_clk_active {
			mux {
				pins = "gpio82";
				function = "qup2_se7";
			};

			config {
				pins = "gpio82";
				drive-strength = <6>;
				bias-disable;
			};
		};

		qupv3_se23_spi_cs_active: qupv3_se23_spi_cs_active {
			mux {
				pins = "gpio83";
				function = "qup2_se7";
			};

			config {
				pins = "gpio83";
				drive-strength = <6>;
				bias-disable;
			};
		};

		qupv3_se23_spi_sleep: qupv3_se23_spi_sleep {
			mux {
				pins = "gpio80", "gpio81",
				       "gpio82", "gpio83";
				function = "gpio";
			};

			config {
				pins = "gpio80", "gpio81",
				       "gpio82", "gpio83";
				drive-strength = <2>;
				bias-disable;
			};
		};
	};

	pcie5 {
		pcie5_perst_init: pcie5_perst_init {
			mux {
				pins = "gpio152";
				function = "gpio";
			};

			config {
				pins = "gpio152";
				drive-strength = <2>;
				bias-pull-down;
				output-low;
			};
		};

		pcie5_perst_default: pcie5_perst_default {
			mux {
				pins = "gpio152";
				function = "gpio";
			};

			config {
				pins = "gpio152";
				drive-strength = <2>;
				bias-pull-down;
			};
		};

		pcie5_clkreq_default: pcie5_clkreq_default {
			mux {
				pins = "gpio153";
				function = "pcie5_clk_req_n";
			};

			config {
				pins = "gpio153";
				drive-strength = <2>;
				bias-pull-up;
			};
		};

		pcie5_wake_default: pcie5_wake_default {
			mux {
				pins = "gpio154";
				function = "gpio";
			};

			config {
				pins = "gpio154";
				drive-strength = <2>;
				bias-pull-up;
			};
		};

		pcie5_clkreq_sleep: pcie5_clkreq_sleep {
			mux {
				pins = "gpio153";
				function = "gpio";
			};

			config {
				pins = "gpio153";
				drive-strength = <2>;
				bias-pull-up;
			};
		};
	};

	pcie4 {
		pcie4_perst_default: pcie4_perst_default {
			mux {
				pins = "gpio146";
				function = "gpio";
			};

			config {
				pins = "gpio146";
				drive-strength = <2>;
				bias-pull-down;
			};
		};

		pcie4_clkreq_default: pcie4_clkreq_default {
			mux {
				pins = "gpio147";
				function = "pcie4_clk_req_n";
			};

			config {
				pins = "gpio147";
				drive-strength = <2>;
				bias-pull-up;
			};
		};

		pcie4_wake_default: pcie4_wake_default {
			mux {
				pins = "gpio148";
				function = "gpio";
			};

			config {
				pins = "gpio148";
				drive-strength = <2>;
				bias-pull-up;
			};
		};

		pcie4_clkreq_sleep: pcie4_clkreq_sleep {
			mux {
				pins = "gpio147";
				function = "gpio";
			};

			config {
				pins = "gpio147";
				drive-strength = <2>;
				bias-pull-up;
			};
		};
	};
	/* WCD reset pin */
	wcd939x_reset_active: wcd939x_reset_active {
		mux {
			pins = "gpio191";
			function = "gpio";
		};

		config {
			pins = "gpio191";
			drive-strength = <16>;
			output-high;
		};
	};

	wcd939x_reset_sleep: wcd939x_reset_sleep {
		mux {
			pins = "gpio191";
			function = "gpio";
		};

		config {
			pins = "gpio191";
			drive-strength = <16>;
			bias-disable;
			output-low;
		};
	};

	i2s0_ws {
		i2s0_ws_sleep: i2s0_ws_sleep {
			mux {
				pins = "gpio138";
				function = "gpio";
			};

			config {
				pins = "gpio138";
				drive-strength = <2>;   /* 2 mA */
				bias-pull-down;         /* PULL DOWN */
				input-enable;
			};
		};

		i2s0_ws_active: i2s0_ws_active {
			mux {
				pins = "gpio138";
				function = "i2s0_ws";
			};

			config {
				pins = "gpio138";
				drive-strength = <8>;   /* 8 mA */
				bias-disable;           /* NO PULL */
			};
		};
	};

	i2s1_sck {
		i2s1_sck_sleep: i2s1_sck_sleep {
			mux {
				pins = "gpio139";
				function = "gpio";
			};

			config {
				pins = "gpio139";
				drive-strength = <2>;   /* 2 mA */
				bias-pull-down;         /* PULL DOWN */
				input-enable;
			};
		};

		i2s1_sck_active: i2s1_sck_active {
			mux {
				pins = "gpio139";
				function = "i2s1_sck";
			};

			config {
				pins = "gpio139";
				drive-strength = <8>;   /* 8 mA */
				bias-disable;           /* NO PULL */
			};
		};
	};

	i2s1_ws {
		i2s1_ws_sleep: i2s1_ws_sleep {
			mux {
				pins = "gpio141";
				function = "gpio";
			};

			config {
				pins = "gpio141";
				drive-strength = <2>;   /* 2 mA */
				bias-pull-down;         /* PULL DOWN */
				input-enable;
			};
		};

		i2s1_ws_active: i2s1_ws_active {
			mux {
				pins = "gpio141";
				function = "i2s1_ws";
			};

			config {
				pins = "gpio141";
				drive-strength = <8>;   /* 8 mA */
				bias-disable;           /* NO PULL */
			};
		};
	};

	i2s1_sd0 {
		i2s1_sd0_sleep: i2s1_sd0_sleep {
			mux {
				pins = "gpio140";
				function = "gpio";
			};

			config {
				pins = "gpio140";
				drive-strength = <2>;   /* 2 mA */
				bias-pull-down;         /* PULL DOWN */
				input-enable;
			};
		};

		i2s1_sd0_active: i2s1_sd0_active {
			mux {
				pins = "gpio140";
				function = "i2s1_data";
			};

			config {
				pins = "gpio140";
				drive-strength = <8>;   /* 8 mA */
				bias-disable;           /* NO PULL */
			};
		};
	};

	i2s1_sd1 {
		i2s1_sd1_sleep: i2s1_sd1_sleep {
			mux {
				pins = "gpio142";
				function = "gpio";
			};

			config {
				pins = "gpio142";
				drive-strength = <2>;   /* 2 mA */
				bias-pull-down;         /* PULL DOWN */
				input-enable;
			};
		};

		i2s1_sd1_active: i2s1_sd1_active {
			mux {
				pins = "gpio142";
				function = "i2s1_data";
			};

			config {
				pins = "gpio142";
				drive-strength = <8>;   /* 8 mA */
				bias-disable;           /* NO PULL */
			};
		};
	};

	i2s0_sd1 {
		i2s0_sd1_sleep: i2s0_sd1_sleep {
			mux {
				pins = "gpio137";
				function = "gpio";
			};

			config {
				pins = "gpio137";
				drive-strength = <2>;   /* 2 mA */
				bias-pull-down;         /* PULL DOWN */
				input-enable;
			};
		};

		i2s0_sd1_active: i2s0_sd1_active {
			mux {
				pins = "gpio137";
				function = "i2s0_data";
			};

			config {
				pins = "gpio137";
				drive-strength = <8>;   /* 8 mA */
				bias-disable;           /* NO PULL */
			};
		};
	};

	i2s0_sd0 {
		i2s0_sd0_sleep: i2s0_sd0_sleep {
			mux {
				pins = "gpio136";
				function = "gpio";
			};

			config {
				pins = "gpio136";
				drive-strength = <2>;   /* 2 mA */
				bias-pull-down;         /* PULL DOWN */
				input-enable;
			};
		};

		i2s0_sd0_active: i2s0_sd0_active {
			mux {
				pins = "gpio136";
				function = "i2s0_data";
			};

			config {
				pins = "gpio136";
				drive-strength = <8>;   /* 8 mA */
				bias-disable;           /* NO PULL */
			};
		};
	};

	i2s0_sck {
		i2s0_sck_sleep: i2s0_sck_sleep {
			mux {
				pins = "gpio135";
				function = "gpio";
			};

			config {
				pins = "gpio135";
				drive-strength = <2>;   /* 2 mA */
				bias-pull-down;         /* PULL DOWN */
				input-enable;
			};
		};

		i2s0_sck_active: i2s0_sck_active {
			mux {
				pins = "gpio135";
				function = "i2s0_sck";
			};

			config {
				pins = "gpio135";
				drive-strength = <8>;   /* 8 mA */
				bias-disable;           /* NO PULL */
			};
		};
	};

	/* WSA speaker - north reset pins */
	spkr_02_sd_n {
		spkr_02_sd_n_sleep: spkr_02_sd_n_sleep {
			mux {
				pins = "gpio204";
				function = "gpio";
			};

			config {
				pins = "gpio204";
				drive-strength = <2>;   /* 2 mA */
				bias-pull-down;
				input-enable;
			};
		};

		spkr_02_sd_n_active: spkr_02_sd_n_active {
			mux {
				pins = "gpio204";
				function = "gpio";
			};

			config {
				pins = "gpio204";
				drive-strength = <16>;   /* 16 mA */
				bias-disable;
				output-high;
			};
		};
	};

	/* WSA speaker - south reset pins */
	spkr_13_sd_n {
		spkr_13_sd_n_sleep: spkr_13_sd_n_sleep {
			mux {
				pins = "gpio205";
				function = "gpio";
			};

			config {
				pins = "gpio205";
				drive-strength = <2>;   /* 2 mA */
				bias-pull-down;
				input-enable;
			};
		};

		spkr_13_sd_n_active: spkr_13_sd_n_active {
			mux {
				pins = "gpio205";
				function = "gpio";
			};

			config {
				pins = "gpio205";
				drive-strength = <16>;   /* 16 mA */
				bias-disable;
				output-high;
			};
		};
	};

	/* WSA speaker - north reset pins */
	spkr_002_sd_n {
		spkr_002_sd_n_sleep: spkr_002_sd_n_sleep {
			mux {
				pins = "gpio209";
				function = "gpio";
			};

			config {
				pins = "gpio209";
				drive-strength = <2>;   /* 2 mA */
				bias-pull-down;
				input-enable;
			};
		};

		spkr_002_sd_n_active: spkr_002_sd_n_active {
			mux {
				pins = "gpio209";
				function = "gpio";
			};

			config {
				pins = "gpio209";
				drive-strength = <16>;   /* 16 mA */
				bias-disable;
				output-high;
			};
		};
	};

	/* WSA speaker - south reset pins */
	spkr_113_sd_n {
		spkr_113_sd_n_sleep: spkr_113_sd_n_sleep {
			mux {
				pins = "gpio210";
				function = "gpio";
			};

			config {
				pins = "gpio210";
				drive-strength = <2>;   /* 2 mA */
				bias-pull-down;
				input-enable;
			};
		};

		spkr_113_sd_n_active: spkr_113_sd_n_active {
			mux {
				pins = "gpio210";
				function = "gpio";
			};

			config {
				pins = "gpio210";
				drive-strength = <16>;   /* 16 mA */
				bias-disable;
				output-high;
			};
		};
	};

	qspi_clk: qspi-clk-state {
		pins = "gpio127";
		function = "qspi0";
		bias-pull-down;
		drive-strength = <6>;
	};

	qspi_data: qspi-data-state {
		pins = "gpio128", "gpio129", "gpio130", "gpio131";
		function = "qspi0";
		bias-pull-down;
		drive-strength = <6>;
	};

	qspi_cs0: qspi-cs0-state {
		pins = "gpio132";
		function = "qspi0";
		bias-disable;
		drive-strength = <6>;
	};

	qspi_sleep: qspi-sleep-state {
		pins = "gpio127", "gpio128", "gpio129", "gpio130", "gpio131", "gpio132";
		function = "gpio";
		output-disable;
	};
};
